# DA14682 register map
Vendor: Dialog; Series: DA14682; File version: 1.2
CPU: CM0 r1p0, little endian, MPU, FPU, 3 interrupt priority bits
Registers are 16-bit, read-write, reset 0x0 unless marked. A register's access mark holds for its fields unless they carry their own. Offsets are from the block's base; [hi:lo] are bit positions.

## UART — UART registers
Base 0x50001000
0x00 UART_RBR_THR_DLL_REG — Receive Buffer Register/Transmit Holding Register/Divisor Latch Low
  [7:0] RBR_THR_DLL — Receive Buffer Register: (RBR). This register contains the data byte received on the serial input port (sin) in UART mode or the serial infrared input (sir_in) in infrared mode. The data in this register is valid only if the Data Ready (DR) bit in the Line status Register (LSR) is set. If FIFOs are disabled (FCR[0] set to zero), the data in the RBR must be read before the next data arrives, otherwise it will be overwritten, resulting in an overrun error. If FIFOs are enabled (FCR[0] set to one), this register accesses the head of the receive FIFO. If the receive FIFO is full and this register is not read before the next data character arrives, then the data already in the FIFO will be preserved but any incoming data will be lost. An overrun error will also occur. Transmit Holding Register: (THR) This register contains data to be transmitted on the serial output port (sout) in UART mode or the serial infrared output (sir_out_n) in infrared mode. Data should only be written to the THR when the THR Empty (THRE) bit (LSR[5]) is set. If FIFO's are disabled (FCR[0] set to zero) and THRE is set, writing a single character to the THR clears the THRE. Any additional writes to the THR before the THRE is set again causes the THR data to be overwritten. If FIFO's are enabled (FCR[0] set to one) and THRE is set, x number of characters of data may be written to the THR before the FIFO is full. The number x (default=16) is determined by the value of FIFO Depth that you set during configuration. Any attempt to write data when the FIFO is full results in the write data being lost. Divisor Latch (Low): (DLL) This register makes up the lower 8-bits of a 16-bit, read/write, Divisor Latch register that contains the baud rate divisor for the UART. This register may only be accessed when the DLAB bit (LCR[7]) is set. The output baud rate is equal to the serial clock (sclk) frequency divided by sixteen times the value of the baud rate divisor, as follows: baud rate = (serial clock freq) / (16 * divisor) Note that with the Divisor Latch Registers (DLL and DLH) set to zero, the baud clock is disabled and no serial communications will occur. Also, once the Divisor Latch is set, at least 8 clock cycles of the slowest UART clock should be allowed to pass before transmitting or receiving data. For the Divisor Latch (High) bits, see register UART_IER_DLH_REG.
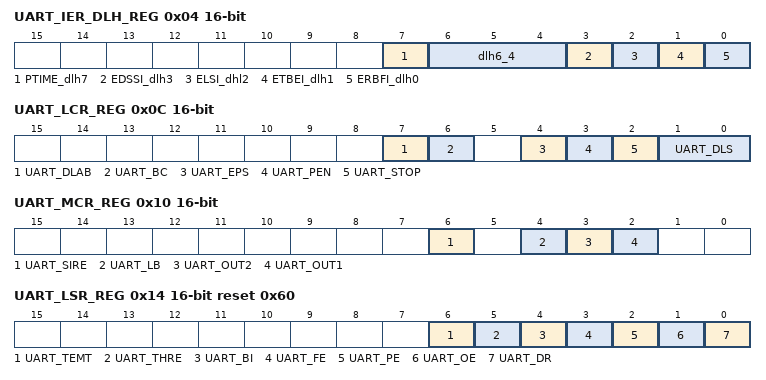
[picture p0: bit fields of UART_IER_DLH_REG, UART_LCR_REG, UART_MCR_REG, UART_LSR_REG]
0x04 UART_IER_DLH_REG — Interrupt Enable Register/Divisor Latch High
  [7] PTIME_dlh7 — Interrupt Enable Register: PTIME, Programmable THRE Interrupt Mode Enable. This is used to enable/disable the generation of THRE Interrupt. 0 = disabled 1 = enabled. Divisor Latch (High): DLH7, Bit 7 of the upper part of a 16-bit, read/write, Divisor Latch register that contains the baud rate divisor for the UART. This register may be accessed only when the DLAB bit (LCR[7]) is set. See register UART_RBR_THR_DLL_REG.
  [6:4] dlh6_4 — Divisor Latch (High): DLH6 to DLH4, Bits 6 to 4 of the upper part of a 16-bit, read/write, Divisor Latch register that contains the baud rate divisor for the UART. This register may be accessed only when the DLAB bit (LCR[7]) is set, otherwise, this field is reserved. See register UART_RBR_THR_DLL_REG.
  [3] EDSSI_dlh3 — Interrupt Enable Register: EDSSI, Enable Modem Status Interrupt. This is used to enable/disable the generation of Modem Status Interrupt. This is the fourth highest priority interrupt. 0 = disabled 1 = enabled Divisor Latch (High): DLH3, Bit 3 of the upper part of a 16-bit, read/write, Divisor Latch register that contains the baud rate divisor for the UART. This register may be accessed only when the DLAB bit (LCR[7]) is set. See register UART_RBR_THR_DLL_REG.
  [2] ELSI_dhl2 — Interrupt Enable Register: ELSI, Enable Receiver Line Status Interrupt. This is used to enable/disable the generation of Receiver Line Status Interrupt. This is the highest priority interrupt. 0 = disabled 1 = enabled Divisor Latch (High): DLH2, Bit 2 of the upper part of a 16-bit, read/write, Divisor Latch register that contains the baud rate divisor for the UART. This register may be accessed only when the DLAB bit (LCR[7]) is set. See register UART_RBR_THR_DLL_REG.
  [1] ETBEI_dlh1 — Interrupt Enable Register: ETBEI, Enable Transmit Holding Register Empty Interrupt. This is used to enable/disable the generation of Transmitter Holding Register Empty Interrupt. This is the third highest priority interrupt. 0 = disabled 1 = enabled Divisor Latch (High): DLH1, Bit 1 of the upper part of a 16-bit, read/write, Divisor Latch register that contains the baud rate divisor for the UART. This register may be accessed only when the DLAB bit (LCR[7]) is set. See register UART_RBR_THR_DLL_REG.
  [0] ERBFI_dlh0 — Interrupt Enable Register: ERBFI, Enable Received Data Available Interrupt. This is used to enable/disable the generation of Received Data Available Interrupt and the Character Timeout Interrupt (if in FIFO mode and FIFO's enabled). These are the second highest priority interrupts. 0 = disabled 1 = enabled Divisor Latch (High): DLH0, Bit 0 of the upper part of a 16-bit, read/write, Divisor Latch register that contains the baud rate divisor for the UART. This register may be accessed only when the DLAB bit (LCR[7]) is set. See register UART_RBR_THR_DLL_REG.
0x08 UART_IIR_FCR_REG — Interrupt Identification Register/FIFO Control Register
  [15:0] IIR_FCR ro — Interrupt Identification Register: Bits[7:6], returns 00. Bits[3:0], Interrupt ID (or IID): This indicates the highest priority pending interrupt which can be one of the following types: 0001 = no interrupt pending. 0010 = THR empty. 0100 = received data available. 0110 = receiver line status. 0111 = busy detect. 1100 = character timeout.
0x0C UART_LCR_REG — Line Control Register
  [7] UART_DLAB — Divisor Latch Access Bit. This bit is used to enable reading and writing of the Divisor Latch register (DLL and DLH) to set the baud rate of the UART. This bit must be cleared after initial baud rate setup in order to access other registers.
  [6] UART_BC — Break Control Bit. This is used to cause a break condition to be transmitted to the receiving device. If set to one the serial output is forced to the spacing (logic 0) state. When not in Loopback Mode, as determined by MCR[4], the sout line is forced low until the Break bit is cleared. If active (MCR[6] set to one) the sir_out_n line is continuously pulsed. When in Loopback Mode, the break condition is internally looped back to the receiver and the sir_out_n line is forced low.
  [4] UART_EPS — Even Parity Select. Writeable only when UART is not busy (USR[0] is zero). This is used to select between even and odd parity, when parity is enabled (PEN set to one). If set to one, an even number of logic 1s is transmitted or checked. If set to zero, an odd number of logic 1s is transmitted or checked.
  [3] UART_PEN — Parity Enable. Writeable only when UART is not busy (USR[0] is zero). This bit is used to enable and disable parity generation and detection in transmitted and received serial character respectively. 0 = parity disabled 1 = parity enabled
  [2] UART_STOP — Number of stop bits. This is used to select the number of stop bits per character that the peripheral transmits and receives. If set to zero, one stop bit is transmitted in the serial data. If set to one and the data bits are set to 5 (LCR[1:0] set to zero) one and a half stop bits is transmitted. Otherwise, two stop bits are transmitted. Note that regardless of the number of stop bits selected, the receiver checks only the first stop bit. 0 = 1 stop bit 1 = 1.5 stop bits when DLS (LCR[1:0]) is zero, else 2 stop bit
  [1:0] UART_DLS — Data Length Select. This is used to select the number of data bits per character that the peripheral transmits and receives. The number of bit that may be selected areas follows: 00 = 5 bits 01 = 6 bits 10 = 7 bits 11 = 8 bits
0x10 UART_MCR_REG — Modem Control Register
  [6] UART_SIRE — SIR Mode Enable. This is used to enable/disable the IrDA SIR Mode features as described in "IrDA 1.0 SIR Protocol". 0 = IrDA SIR Mode disabled 1 = IrDA SIR Mode enabled
  [4] UART_LB — LoopBack Bit. This is used to put the UART into a diagnostic mode for test purposes. If operating in UART mode (SIR_MODE not active, MCR[6] set to zero), data on the sout line is held high, while serial data output is looped back to the sin line, internally. In this mode all the interrupts are fully functional. Also, in loopback mode, the modem control inputs (dsr_n, cts_n, ri_n, dcd_n) are disconnected and the modem control outputs (dtr_n, rts_n, out1_n, out2_n) are looped back to the inputs, internally. If operating in infrared mode (SIR_MODE active, MCR[6] set to one), data on the sir_out_n line is held low, while serial data output is inverted and looped back to the sir_in line.
  [3] UART_OUT2 — OUT2. This is used to directly control the user-designated Output2 (out2_n) output. The value written to this location is inverted and driven out on out2_n, that is: 0 = out2_n de-asserted (logic 1) 1 = out2_n asserted (logic 0) Note that in Loopback mode (MCR[4] set to one), the out2_n output is held inactive high while the value of this location is internally looped back to an input.
  [2] UART_OUT1 — OUT1. This is used to directly control the user-designated Output1 (out1_n) output. The value written to this location is inverted and driven out on out1_n, that is: 0 = out1_n de-asserted (logic 1) 1 = out1_n asserted (logic 0) Note that in Loopback mode (MCR[4] set to one), the out1_n output is held inactive high while the value of this location is internally looped back to an input.
0x14 UART_LSR_REG reset 0x60 — Line Status Register
  [6] UART_TEMT ro — Transmitter Empty bit. This bit is set whenever the Transmitter Holding Register and the Transmitter Shift Register are both empty.
  [5] UART_THRE ro — Transmit Holding Register Empty bit. If THRE mode is disabled (IER[7] set to zero), this bit indicates that the THR. This bit is set whenever data is transferred from the THR to the transmitter shift register and no new data has been written to the THR. This also causes a THRE Interrupt to occur, if the THRE Interrupt is enabled.
  [4] UART_BI ro — Break Interrupt bit. This is used to indicate the detection of a break sequence on the serial input data. If in UART mode (SIR_MODE == Disabled), it is set whenever the serial input, sin, is held in a logic '0' state for longer than the sum of start time + data bits + parity + stop bits. If in infrared mode (SIR_MODE == Enabled), it is set whenever the serial input, sir_in, is continuously pulsed to logic '0' for longer than the sum of start time + data bits + parity + stop bits. A break condition on serial input causes one and only one character, consisting of all zeros, to be received by the UART. Reading the LSR clears the BI bit. The BI indication occurs immediately and persists until the LSR is read.
  [3] UART_FE ro — Framing Error bit. This is used to indicate the occurrence of a framing error in the receiver. A framing error occurs when the receiver does not detect a valid STOP bit in the received data. When a framing error occurs, the UART tries to resynchronize. It does this by assuming that the error was due to the start bit of the next character and then continues receiving the other bit i.e. data, and/or parity and stop. It should be noted that the Framing Error (FE) bit (LSR[3]) is set if a break interrupt has occurred, as indicated by Break Interrupt (BI) bit (LSR[4]). 0 = no framing error 1 = framing error Reading the LSR clears the FE bit.
  [2] UART_PE ro — Parity Error bit. This is used to indicate the occurrence of a parity error in the receiver if the Parity Enable (PEN) bit (LCR[3]) is set. It should be noted that the Parity Error (PE) bit (LSR[2]) is set if a break interrupt has occurred, as indicated by Break Interrupt (BI) bit (LSR[4]). 0 = no parity error 1 = parity error Reading the LSR clears the PE bit.
  [1] UART_OE ro — Overrun error bit. This is used to indicate the occurrence of an overrun error. This occurs if a new data character was received before the previous data was read. The OE bit is set when a new character arrives in the receiver before the previous character was read from the RBR. When this happens, the data in the RBR is overwritten. 0 = no overrun error 1 = overrun error Reading the LSR clears the OE bit.
  [0] UART_DR ro — Data Ready bit. This is used to indicate that the receiver contains at least one character in the RBR. 0 = no data ready 1 = data ready This bit is cleared when the RBR is read.
0x1C UART_SCR_REG — Scratchpad Register
  [7:0] UART_SCRATCH_PAD — This register is for programmers to use as a temporary storage space. It has no defined purpose in the UART Ctrl.
0x7C UART_USR_REG — UART Status register.
  [0] UART_BUSY ro — UART Busy. This indicates that a serial transfer is in progress, when cleared indicates that the DW_apb_uart is idle or inactive. 0 - DW_apb_uart is idle or inactive 1 - DW_apb_uart is busy (actively transferring data) Note that it is possible for the UART Busy bit to be cleared even though a new character may have been sent from another device. That is, if the DW_apb_uart has no data in the THR and RBR and there is no transmission in progress and a start bit of a new character has just reached the DW_apb_uart. This is due to the fact that a valid start is not seen until the middle of the bit period and this duration is dependent on the baud divisor that has been programmed. If a second system clock has been implemented (CLOCK_MODE == Enabled) the assertion of this bit will also be delayed by several cycles of the slower clock.
0x88 UART_SRR_REG — Software Reset Register.
  [0] UART_UR wo — UART Reset. This asynchronously resets the UART Ctrl and synchronously removes the reset assertion. For a two clock implementation both pclk and sclk domains are reset.
0x90 UART_SBCR_REG — Shadow Break Control Register
  [0] UART_SHADOW_BREAK_CONTROL — Shadow Break Control Bit. This is a shadow register for the Break bit (LCR[6]), this can be used to remove the burden of having to performing a read modify write on the LCR. This is used to cause a break condition to be transmitted to the receiving device. If set to one the serial output is forced to the spacing (logic 0) state. When not in Loopback Mode, as determined by MCR[4], the sout line is forced low until the Break bit is cleared. If SIR_MODE active (MCR[6] = 1) the sir_out_n line is continuously pulsed. When in Loopback Mode, the break condition is internally looped back to the receiver.
0xA8 UART_DMASA_REG — DMA Software Acknowledge
  [0] DMASA wo — This register is use to perform DMA software acknowledge if a transfer needs to be terminated due to an error condition. For example, if the DMA disables the channel, then the DW_apb_uart should clear its request. This will cause the TX request, TX single, RX request and RX single signals to de-assert. Note that this bit is 'self-clearing' and it is not necessary to clear this bit.
0xC0 UART_DLF_REG — Divisor Latch Fraction Register
  [3:0] UART_DLF — The fractional value is added to integer value set by DLH, DLL. Fractional value is determined by (Divisor Fraction value)/(2^DLF_SIZE).
0xF4 UART_CPR_REG reset 0x3941 — Component Parameter Register
  [15:0] CPR ro
0xF8 UART_UCV_REG 32-bit reset 0x331352A (reset mask 0xFFFF) — Component Version
  [31:0] UCV ro
0xFC UART_CTR_REG 32-bit reset 0x44570110 (reset mask 0xFFFF) — Component Type Register
  [31:0] CTR ro
